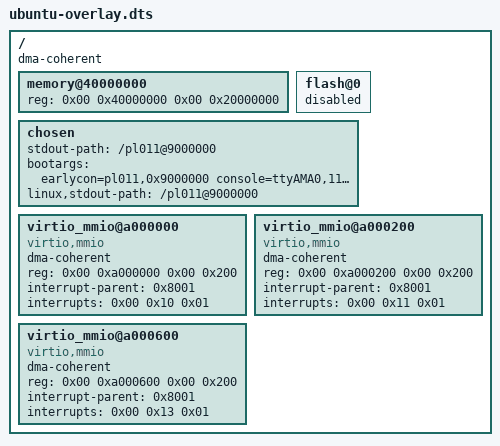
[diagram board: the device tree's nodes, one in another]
/*
 * agentOS Ubuntu guest overlay DTS — QEMU virt AArch64
 *
 * SPDX-License-Identifier: BSD-2-Clause
 *
 * Merged with linux.dts by dtscat to produce vm.dtb.
 * Differences from buildroot overlay:
 *   - No initrd (Ubuntu 24.04 minimal uses GRUB_FORCE_PARTUUID initrdless boot)
 *   - Root via virtio-blk disk: root=PARTUUID=6cb74abd-5e56-4fc1-a7be-4ad74dbbe860
 *   - Adds virtio_mmio@a000200 for virtio-blk (slot 1, SPI 17 → INTID 49)
 */
/ {
    dma-coherent;

    /* 512MB guest RAM — matches linux_vmm guest_ram MR in system_desc_aarch64.c */
    memory@40000000 {
        device_type = "memory";
        reg = <0x00 0x40000000 0x00 0x20000000>;
    };

    flash@0 {
        status = "disabled";
    };

    chosen {
        stdout-path = "/pl011@9000000";
        /* Ubuntu 24.04 cloud image: initrdless boot via device path.
         * vda = first virtio-blk (ubuntu disk), vda1 = root partition.
         * cloud-init reads NoCloud data from QEMU user-net host 10.0.2.2.
         * earlycon/console through PL011 at 0x9000000. */
        bootargs = "earlycon=pl011,0x9000000 console=ttyAMA0,115200 root=/dev/vda1 rw systemd.unit=multi-user.target systemd.mask=boot.mount systemd.mask=boot-efi.mount systemd.mask=multipathd.service systemd.mask=multipathd.socket ds=nocloud-net;s=http://10.0.2.2:18790/";
        linux,stdout-path = "/pl011@9000000";
    };

    /*
     * virtio-net passthrough: QEMU virt virtio-mmio slot 0.
     * Physical address: 0xa000000 + 0*0x200 = 0xa000000.
     * IRQ: SPI 16 (INTID 48) — QEMU assigns SPI (16+slot) per transport.
     * Slot 0 is chosen explicitly: QEMU command uses bus=virtio-mmio-bus.0.
     * interrupt-parent 0x8001 = intc@8000000 (GIC) phandle in linux.dts.
     * trigger 0x01 = edge-rising (matches QEMU's virt machine DT for slot 0).
     */
    virtio_mmio@a000000 {
        compatible = "virtio,mmio";
        dma-coherent;
        reg = <0x00 0xa000000 0x00 0x200>;
        interrupt-parent = <0x8001>;
        interrupts = <0x00 0x10 0x01>;
    };

    /*
     * virtio-blk passthrough: QEMU virt virtio-mmio slot 1.
     * Physical address: 0xa000000 + 1*0x200 = 0xa000200.
     * IRQ: SPI 17 (INTID 49) — slot 1 = ubuntu root disk (vda).
     * trigger 0x01 = edge-rising.
     */
    virtio_mmio@a000200 {
        compatible = "virtio,mmio";
        dma-coherent;
        reg = <0x00 0xa000200 0x00 0x200>;
        interrupt-parent = <0x8001>;
        interrupts = <0x00 0x11 0x01>;
    };

    /*
     * virtio-blk passthrough: QEMU virt virtio-mmio slot 3.
     * Physical address: 0xa000000 + 3*0x200 = 0xa000600.
     * IRQ: SPI 19 (INTID 51) — slot 3 = cloud-init seed (vdb, label CIDATA).
     * Slot 2 is reserved for cc_pd's host command relay.
     * trigger 0x01 = edge-rising.
     */
    virtio_mmio@a000600 {
        compatible = "virtio,mmio";
        dma-coherent;
        reg = <0x00 0xa000600 0x00 0x200>;
        interrupt-parent = <0x8001>;
        interrupts = <0x00 0x13 0x01>;
    };
};
